# CY8C5888LTI_LP097 register map
File version: 0.1
CY8C58LP
Registers are 32-bit, read-write, no defined reset value unless marked. A register's access mark holds for its fields unless they carry their own. Offsets are from the block's base; lines under a group give offsets from that group; [hi:lo] are bit positions; {n}, {i} and the like mark numbered series; 'fields as' and 'values as' point back to an identical list; <NAME> marks a mode.

## Memory map
0x00000000 CAN_1
0x00000000 JOYSTICK_ADC_XY_SAR — SAR ADC
0x00000000 UART_LOG — UART
0x00000000 PWM_RGB_Red
0x00000000 PWM_RGB_Green
0x00000000 PWM_RGB_Blue

## CAN_1
Base 0x00000000
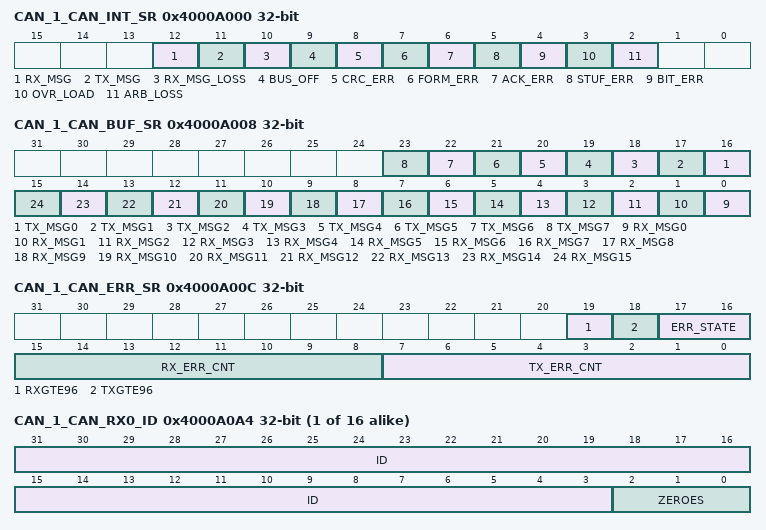
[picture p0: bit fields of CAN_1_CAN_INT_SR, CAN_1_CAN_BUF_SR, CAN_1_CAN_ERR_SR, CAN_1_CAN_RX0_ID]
0x4000A000 CAN_1_CAN_INT_SR — The interrupt status register stores internal interrupt events. ? Once a bit is set it remains set until it is cleared by writing a '1' to it. ? The interrupt enable register has no effect on the interrupt status register. ? A pending interrupt occurs when the flag is set to '1'. To acknowledge an interrupt, set the flag to '1'
  [12] RX_MSG — Msg Recieved
  [11] TX_MSG — Tx msg Sent
  [10] RX_MSG_LOSS — Rx msg loss Interrupt
  [9] BUS_OFF — Bus Off State
  [8] CRC_ERR — CRC Error Interrupt
  [7] FORM_ERR — Form Error Interrupt
  [6] ACK_ERR — Ack Error Interrupt
  [5] STUF_ERR — Stuff Error Interrupt
  [4] BIT_ERR — Bit Error Interrupt
  [3] OVR_LOAD — Overload Interrupt
  [2] ARB_LOSS — Arbitration Loss
0x4000A008 CAN_1_CAN_BUF_SR — These status indicators bundle the respective flags from all RxMessage and TxMessage buffers. ? Note All flags are read only. To acknowledge a MsgAv flag, the CPU must write to the respective RxMessage buffer
  [n+16] TX_MSG{n} (n=0..7) — Tx req Pending for Tx Msg{n}
  [n] RX_MSG{n} (n=0..15) — Rx Msg{n} Available
0x4000A00C CAN_1_CAN_ERR_SR — Status indicators are provided to report the CAN controller error state, receive error count, and transmit error count. ? Special flags report error counter values equal to or in excess of 96 errors are available to indicate heavily disturbed bus situations. ? The transmitter error counter according to the CAN standard. When it is greater than 255 Decimal, it is fixed at 255 Decimal.
  [19] RXGTE96 — Rx Error Count is greater or equal to 96 Decimal
  [18] TXGTE96 — Tx Error Count is greater or equal to 96 Decimal
  [17:16] ERR_STATE — Error State of CAN node, 00 error active, 01 error passive, 1x bus off
  [15:8] RX_ERR_CNT — Rx error Count. When in bus-off state,this counter is used to count 128 groups of 11 recessive bits
  [7:0] TX_ERR_CNT — Tx error Count
{0x4000A024+0x10*i} CAN_1_CAN_TX{i}_ID (i=0..7) — CAN Tx Msg Identifier
  [31:3] ID — Tx Msg Indentifier
{0x4000A028+0x10*i} CAN_1_CAN_TX{i}_DH (i=0..7) — CAN Tx Msg Upper Data Bytes
  [31:0] DATA_HIGH — Upper Data Bytes
{0x4000A02C+0x10*i} CAN_1_CAN_TX{i}_DL (i=0..7) — CAN Tx Msg Lower Data Bytes
  [31:0] DATA_LOW — Lower Data Bytes
{0x4000A0A4+0x20*i} CAN_1_CAN_RX{i}_ID (i=0..15) — The register contains Rx Msg Identifier
  [31:3] ID — Rx Msg Indentifier
  [2:0] ZEROES — zeros
{0x4000A0A8+0x20*i} CAN_1_CAN_RX{i}_DH (i=0..15) — The register contains the Rx Msg Upper Data Bytes
  [31:0] DATA_HIGH — Upper Data Bytes
{0x4000A0AC+0x20*i} CAN_1_CAN_RX{i}_DL (i=0..15) — The register contains the Rx Msg Lover Data Bytes
  [31:0] DATA_LOW — Lower Data Bytes

## JOYSTICK_ADC_XY_SAR — SAR ADC
Base 0x00000000
0x40004614 SAR_TR0 8-bit — SAR trim register
{0x40005900+i} SAR_CSR{i} 8-bit (i=0..6) — SAR status and control register {i}
0x40005B20 SAR_SW0 8-bit — SAR Analog Routing Register 0
{0x40005B20+i} SAR_SW{i} 8-bit (i=2..4) — SAR Analog Routing Register {i}
0x40005B26 SAR_SW6 8-bit — SAR Analog Routing Register 6
0x40005B27 SAR_CLK 8-bit — SAR Clock Selection Register
0x40005BA0 SAR_WRK 16-bit — SAR working register

## UART_LOG — UART
Base 0x00000000
0x40006441 TX_UART_LOG_TX_DATA 8-bit — TX Data Register
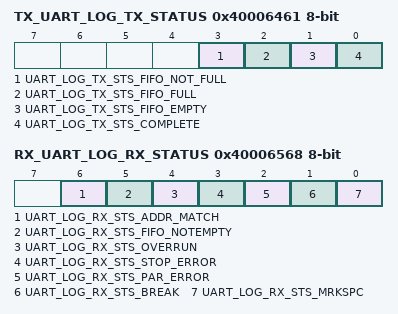
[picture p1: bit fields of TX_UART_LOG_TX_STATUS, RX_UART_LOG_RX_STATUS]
0x40006461 TX_UART_LOG_TX_STATUS 8-bit — TX status register
  [3] UART_LOG_TX_STS_FIFO_NOT_FULL ro, [2] UART_LOG_TX_STS_FIFO_FULL ro, [1] UART_LOG_TX_STS_FIFO_EMPTY ro, [0] UART_LOG_TX_STS_COMPLETE ro
0x4000652A RX_UART_LOG_RX_ADDRESS1 8-bit — RX Address1 Register
0x4000653A RX_UART_LOG_RX_ADDRESS2 8-bit — RX Address2 Register
0x4000654A RX_UART_LOG_RX_DATA 8-bit — RX Data Register
0x40006568 RX_UART_LOG_RX_STATUS 8-bit — RX status register
  [6] UART_LOG_RX_STS_ADDR_MATCH ro, [5] UART_LOG_RX_STS_FIFO_NOTEMPTY ro, [4] UART_LOG_RX_STS_OVERRUN ro, [3] UART_LOG_RX_STS_STOP_ERROR ro, [2] UART_LOG_RX_STS_PAR_ERROR ro, [1] UART_LOG_RX_STS_BREAK ro, [0] UART_LOG_RX_STS_MRKSPC ro
